AUTOSAR XML (schema 4.0)
package /Battery_EV_Components
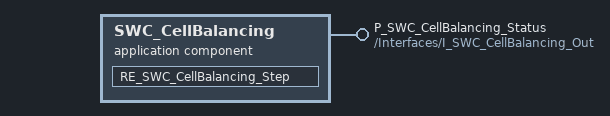
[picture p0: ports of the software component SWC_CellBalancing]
  application sw component type SWC_CellBalancing  # AUTOSAR Application SWC SWC_CellBalancing for Battery EV Safety
    provide port P_SWC_CellBalancing_Status: provided-interface=/Interfaces/I_SWC_CellBalancing_Out
    behavior SWC_CellBalancing_Behavior
      runnable RE_SWC_CellBalancing_Step: symbol=SWC_CellBalancing_Step
  sender receiver interface I_SWC_CellBalancing_Out
    data DE_SWC_CellBalancing_Health: type=/AUTOSAR/Platform/uint32
